# mc200 register map
Registers are 32-bit, access not given, no defined reset value unless marked. A register's access mark holds for its fields unless they carry their own. Addresses are absolute; registers are grouped by the start of their names; [hi:lo] are bit positions.

## CRC
0x44005000 CRC_ISR
  [0] STATUS
0x44005004 CRC_IRSR
  [0] STATUS_RAW_0
0x44005008 CRC_ICR
  [0] CLEAR
0x4400500C CRC_IMR
  [0] MASK
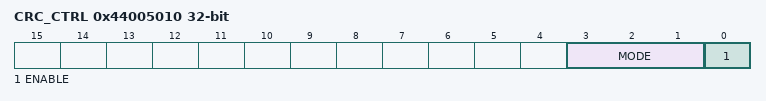
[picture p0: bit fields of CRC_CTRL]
0x44005010 CRC_CTRL
  [3:1] MODE, [0] ENABLE
0x44005014 CRC_STREAM_LEN_M1
  [31:0] LENGTH_M1
0x44005018 CRC_STREAM_IN
  [31:0] DATA
0x4400501C CRC_RESULT
  [31:0] DATA

## I2C0
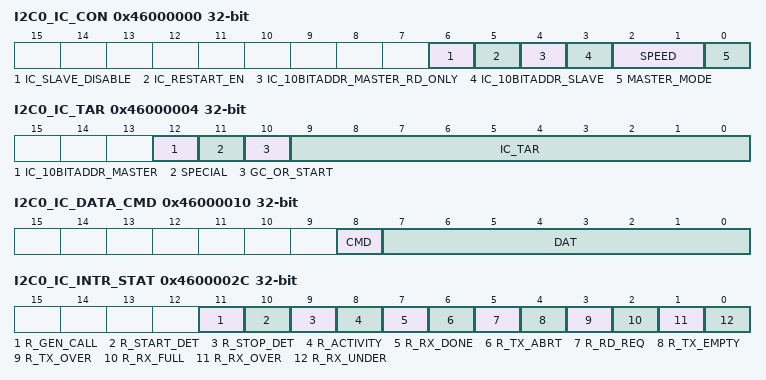
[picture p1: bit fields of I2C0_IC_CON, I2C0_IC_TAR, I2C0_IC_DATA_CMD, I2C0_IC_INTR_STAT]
0x46000000 I2C0_IC_CON
  [6] IC_SLAVE_DISABLE, [5] IC_RESTART_EN, [4] IC_10BITADDR_MASTER_RD_ONLY, [3] IC_10BITADDR_SLAVE, [2:1] SPEED, [0] MASTER_MODE
0x46000004 I2C0_IC_TAR
  [12] IC_10BITADDR_MASTER, [11] SPECIAL, [10] GC_OR_START, [9:0] IC_TAR
0x46000008 I2C0_IC_SAR
  [9:0] IC_SAR
0x4600000C I2C0_IC_HS_MADDR
  [2:0] IC_HS_MAR
0x46000010 I2C0_IC_DATA_CMD
  [8] CMD, [7:0] DAT
0x46000014 I2C0_IC_SS_SCL_HCNT
  [15:0] IC_SS_SCL_HCNT
0x46000018 I2C0_IC_SS_SCL_LCNT
  [15:0] IC_SS_SCL_LCNT
0x4600001C I2C0_IC_FS_SCL_HCNT
  [15:0] IC_FS_SCL_HCNT
0x46000020 I2C0_IC_FS_SCL_LCNT
  [15:0] IC_FS_SCL_LCNT
0x46000024 I2C0_IC_HS_SCL_HCNT
  [15:0] IC_HS_SCL_HCNT
0x46000028 I2C0_IC_HS_SCL_LCNT
  [15:0] IC_HS_SCL_LCNT
0x4600002C I2C0_IC_INTR_STAT
  [11] R_GEN_CALL, [10] R_START_DET, [9] R_STOP_DET, [8] R_ACTIVITY, [7] R_RX_DONE, [6] R_TX_ABRT, [5] R_RD_REQ, [4] R_TX_EMPTY, [3] R_TX_OVER, [2] R_RX_FULL, [1] R_RX_OVER, [0] R_RX_UNDER
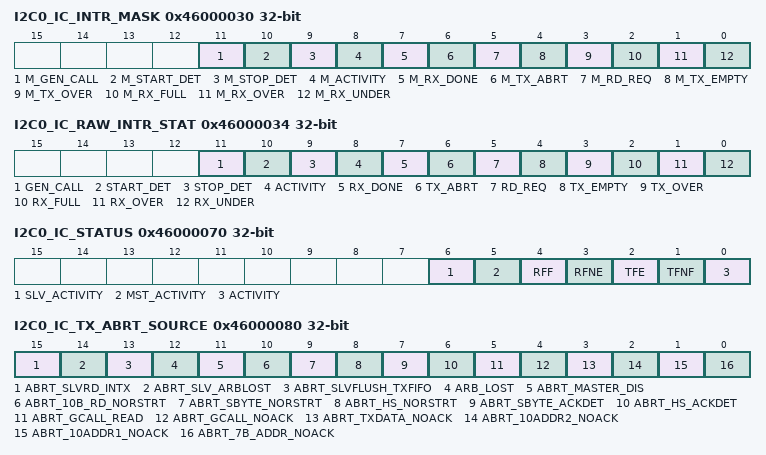
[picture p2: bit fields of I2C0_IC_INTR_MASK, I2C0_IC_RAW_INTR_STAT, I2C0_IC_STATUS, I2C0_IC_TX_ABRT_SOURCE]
0x46000030 I2C0_IC_INTR_MASK
  [11] M_GEN_CALL, [10] M_START_DET, [9] M_STOP_DET, [8] M_ACTIVITY, [7] M_RX_DONE, [6] M_TX_ABRT, [5] M_RD_REQ, [4] M_TX_EMPTY, [3] M_TX_OVER, [2] M_RX_FULL, [1] M_RX_OVER, [0] M_RX_UNDER
0x46000034 I2C0_IC_RAW_INTR_STAT
  [11] GEN_CALL, [10] START_DET, [9] STOP_DET, [8] ACTIVITY, [7] RX_DONE, [6] TX_ABRT, [5] RD_REQ, [4] TX_EMPTY, [3] TX_OVER, [2] RX_FULL, [1] RX_OVER, [0] RX_UNDER
0x46000038 I2C0_IC_RX_TL
  [7:0] RX_TL
0x4600003C I2C0_IC_TX_TL
  [7:0] TX_TL
0x46000040 I2C0_IC_CLR_INTR
  [0] CLR_INTR
0x46000044 I2C0_IC_CLR_RX_UNDER
  [0] CLR_RX_UNDER
0x46000048 I2C0_IC_CLR_RX_OVER
  [0] CLR_RX_OVER
0x4600004C I2C0_IC_CLR_TX_OVER
  [0] CLR_TX_OVER
0x46000050 I2C0_IC_CLR_RD_REQ
  [0] CLR_RD_REQ
0x46000054 I2C0_IC_CLR_TX_ABRT
  [0] CLR_TX_ABRT
0x46000058 I2C0_IC_CLR_RX_DONE
  [0] CLR_RX_DONE
0x4600005C I2C0_IC_CLR_ACTIVITY
  [0] CLR_ACTIVITY
0x46000060 I2C0_IC_CLR_STOP_DET
  [0] CLR_STOP_DET
0x46000064 I2C0_IC_CLR_START_DET
  [0] CLR_START_DET
0x46000068 I2C0_IC_CLR_GEN_CALL
  [0] CLR_GEN_CALL
0x4600006C I2C0_IC_ENABLE
  [0] ENABLE
0x46000070 I2C0_IC_STATUS
  [6] SLV_ACTIVITY, [5] MST_ACTIVITY, [4] RFF, [3] RFNE, [2] TFE, [1] TFNF, [0] ACTIVITY
0x46000074 I2C0_IC_TXFLR
  [4:0] TXFLR
0x46000078 I2C0_IC_RXFLR
  [4:0] RXFLR
0x4600007C I2C0_IC_SDA_HOLD
  [15:0] IC_SDA_HOLD
0x46000080 I2C0_IC_TX_ABRT_SOURCE
  [15] ABRT_SLVRD_INTX, [14] ABRT_SLV_ARBLOST, [13] ABRT_SLVFLUSH_TXFIFO, [12] ARB_LOST, [11] ABRT_MASTER_DIS, [10] ABRT_10B_RD_NORSTRT, [9] ABRT_SBYTE_NORSTRT, [8] ABRT_HS_NORSTRT, [7] ABRT_SBYTE_ACKDET, [6] ABRT_HS_ACKDET, [5] ABRT_GCALL_READ, [4] ABRT_GCALL_NOACK, [3] ABRT_TXDATA_NOACK, [2] ABRT_10ADDR2_NOACK, [1] ABRT_10ADDR1_NOACK, [0] ABRT_7B_ADDR_NOACK
0x46000084 I2C0_IC_SLV_DATA_NACK_ONLY
  [0] NACK
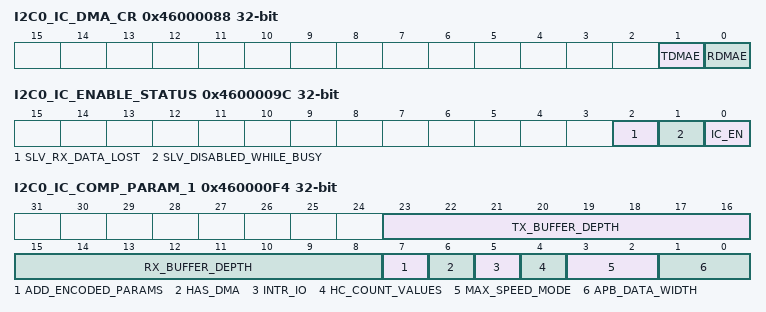
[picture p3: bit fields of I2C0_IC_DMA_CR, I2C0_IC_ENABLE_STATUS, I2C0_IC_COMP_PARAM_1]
0x46000088 I2C0_IC_DMA_CR
  [1] TDMAE, [0] RDMAE
0x4600008C I2C0_IC_DMA_TDLR
  [3:0] DMATDL
0x46000090 I2C0_IC_DMA_RDLR
  [3:0] DMARDL
0x46000094 I2C0_IC_SDA_SETUP
  [7:0] SDA_SETUP
0x46000098 I2C0_IC_ACK_GENERAL_CALL
  [0] ACK_GEN_CALL
0x4600009C I2C0_IC_ENABLE_STATUS
  [2] SLV_RX_DATA_LOST, [1] SLV_DISABLED_WHILE_BUSY, [0] IC_EN
0x460000A0 I2C0_IC_FS_SPKLEN
  [7:0] IC_FS_SPKLEN
0x460000A4 I2C0_IC_HS_SPKLEN
  [7:0] IC_HS_SPKLEN
0x460000F4 I2C0_IC_COMP_PARAM_1
  [23:16] TX_BUFFER_DEPTH, [15:8] RX_BUFFER_DEPTH, [7] ADD_ENCODED_PARAMS, [6] HAS_DMA, [5] INTR_IO, [4] HC_COUNT_VALUES, [3:2] MAX_SPEED_MODE, [1:0] APB_DATA_WIDTH
0x460000F8 I2C0_IC_COMP_VERSION
  [31:0] IC_COMP_VERSION
0x460000FC I2C0_IC_COMP_TYPE
  [31:0] IC_COMP_TYPE
